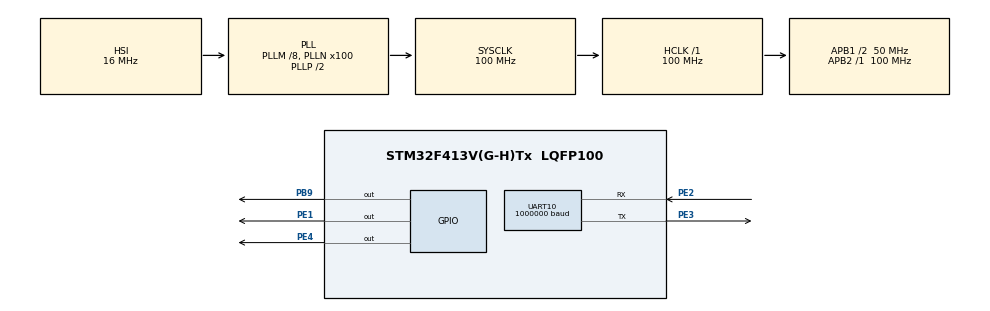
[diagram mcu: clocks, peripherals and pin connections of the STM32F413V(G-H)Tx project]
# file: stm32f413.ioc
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Mcu.Family=STM32F4
Mcu.Name=STM32F413V(G-H)Tx
Mcu.Package=LQFP100
NVIC.PriorityGroup=NVIC_PRIORITYGROUP_4
PB3.Signal=SYS_JTDO-SWO
PB9.Signal=GPIO_Output
PE1.Signal=GPIO_Output
PE2.Mode=Asynchronous
PE2.Signal=UART10_RX
PE3.Mode=Asynchronous
PE3.Signal=UART10_TX
PE4.Signal=GPIO_Output
PH0\ -\ OSC_IN.Mode=HSE-External-Oscillator
PH0\ -\ OSC_IN.Signal=RCC_OSC_IN
PH1\ -\ OSC_OUT.Mode=HSE-External-Oscillator
PH1\ -\ OSC_OUT.Signal=RCC_OSC_OUT
ProjectManager.HeapSize=0x2000
ProjectManager.StackSize=0x4000
ProjectManager.TargetToolchain=Makefile
RCC.AHBFreq_Value=100000000
RCC.APB1CLKDivider=RCC_HCLK_DIV2
RCC.APB1Freq_Value=50000000
RCC.APB1TimFreq_Value=100000000
RCC.APB2Freq_Value=100000000
RCC.APB2TimFreq_Value=100000000
RCC.CortexFreq_Value=100000000
RCC.HCLKFreq_Value=100000000
RCC.HSE_VALUE=8000000
RCC.PLLM=8
RCC.PLLN=100
RCC.SYSCLKFreq_VALUE=100000000
RCC.SYSCLKSource=RCC_SYSCLKSOURCE_PLLCLK
RCC.USBFreq_Value=100000000
RCC.VCOOutputFreq_Value=200000000
UART10.BaudRate=1000000
UART10.VirtualMode=Asynchronous
board=custom

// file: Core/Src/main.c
/* USER CODE BEGIN Header */
/**
  ******************************************************************************
  * @file           : main.c
  * @brief          : Main program body
  ******************************************************************************
  * @attention
  *
  * <h2><center>&copy; Copyright (c) 2021 STMicroelectronics.
  * All rights reserved.</center></h2>
  *
  * This software component is licensed by ST under BSD 3-Clause license,
  * the "License"; You may not use this file except in compliance with the
  * License. You may obtain a copy of the License at:
  *                        opensource.org/licenses/BSD-3-Clause
  *
  ******************************************************************************
  */
/* USER CODE END Header */
#include "main.h"

/* USER CODE BEGIN Includes */
extern void application_main();
/* USER CODE END Includes */

UART_HandleTypeDef huart10;

void SystemClock_Config(void);
static void MX_GPIO_Init(void);
static void MX_UART10_Init(void);

int main(void)
{

  /* MCU Configuration--------------------------------------------------------*/

  /* Reset of all peripherals, Initializes the Flash interface and the Systick. */
  HAL_Init();

  /* Configure the system clock */
  SystemClock_Config();

  /* Initialize all configured peripherals */
  MX_GPIO_Init();
  MX_UART10_Init();
  /* USER CODE BEGIN 2 */
  application_main();
  /* USER CODE END 2 */

  /* Infinite loop */
  while (1)
  {

  }
}

void SystemClock_Config(void)
{
  RCC_OscInitTypeDef RCC_OscInitStruct = {0};
  RCC_ClkInitTypeDef RCC_ClkInitStruct = {0};

  /** Configure the main internal regulator output voltage
  */
  __HAL_RCC_PWR_CLK_ENABLE();
  __HAL_PWR_VOLTAGESCALING_CONFIG(PWR_REGULATOR_VOLTAGE_SCALE1);
  /** Initializes the RCC Oscillators according to the specified parameters
  * in the RCC_OscInitTypeDef structure.
  */
  RCC_OscInitStruct.OscillatorType = RCC_OSCILLATORTYPE_HSI;
  RCC_OscInitStruct.HSIState = RCC_HSI_ON;
  RCC_OscInitStruct.HSICalibrationValue = RCC_HSICALIBRATION_DEFAULT;
  RCC_OscInitStruct.PLL.PLLState = RCC_PLL_ON;
  RCC_OscInitStruct.PLL.PLLSource = RCC_PLLSOURCE_HSI;
  RCC_OscInitStruct.PLL.PLLM = 8;
  RCC_OscInitStruct.PLL.PLLN = 100;
  RCC_OscInitStruct.PLL.PLLP = RCC_PLLP_DIV2;
  RCC_OscInitStruct.PLL.PLLQ = 2;
  RCC_OscInitStruct.PLL.PLLR = 2;
  if (HAL_RCC_OscConfig(&RCC_OscInitStruct) != HAL_OK)
  {
    Error_Handler();
  }
  /** Initializes the CPU, AHB and APB buses clocks
  */
  RCC_ClkInitStruct.ClockType = RCC_CLOCKTYPE_HCLK|RCC_CLOCKTYPE_SYSCLK
                              |RCC_CLOCKTYPE_PCLK1|RCC_CLOCKTYPE_PCLK2;
  RCC_ClkInitStruct.SYSCLKSource = RCC_SYSCLKSOURCE_PLLCLK;
  RCC_ClkInitStruct.AHBCLKDivider = RCC_SYSCLK_DIV1;
  RCC_ClkInitStruct.APB1CLKDivider = RCC_HCLK_DIV2;
  RCC_ClkInitStruct.APB2CLKDivider = RCC_HCLK_DIV1;

  if (HAL_RCC_ClockConfig(&RCC_ClkInitStruct, FLASH_LATENCY_3) != HAL_OK)
  {
    Error_Handler();
  }
}

static void MX_UART10_Init(void)
{

  huart10.Instance = UART10;
  huart10.Init.BaudRate = 1000000;
  huart10.Init.WordLength = UART_WORDLENGTH_8B;
  huart10.Init.StopBits = UART_STOPBITS_1;
  huart10.Init.Parity = UART_PARITY_NONE;
  huart10.Init.Mode = UART_MODE_TX_RX;
  huart10.Init.HwFlowCtl = UART_HWCONTROL_NONE;
  huart10.Init.OverSampling = UART_OVERSAMPLING_16;
  if (HAL_UART_Init(&huart10) != HAL_OK)
  {
    Error_Handler();
  }

}

static void MX_GPIO_Init(void)
{
  GPIO_InitTypeDef GPIO_InitStruct = {0};

  /* GPIO Ports Clock Enable */
  __HAL_RCC_GPIOE_CLK_ENABLE();
  __HAL_RCC_GPIOH_CLK_ENABLE();
  __HAL_RCC_GPIOB_CLK_ENABLE();

  /*Configure GPIO pin Output Level */
  HAL_GPIO_WritePin(GPIOE, GPIO_PIN_4|GPIO_PIN_1, GPIO_PIN_RESET);

  /*Configure GPIO pin Output Level */
  HAL_GPIO_WritePin(GPIOB, GPIO_PIN_9, GPIO_PIN_RESET);

  /*Configure GPIO pins : PE4 PE1 */
  GPIO_InitStruct.Pin = GPIO_PIN_4|GPIO_PIN_1;
  GPIO_InitStruct.Mode = GPIO_MODE_OUTPUT_PP;
  GPIO_InitStruct.Pull = GPIO_NOPULL;
  GPIO_InitStruct.Speed = GPIO_SPEED_FREQ_LOW;
  HAL_GPIO_Init(GPIOE, &GPIO_InitStruct);

  /*Configure GPIO pin : PB9 */
  GPIO_InitStruct.Pin = GPIO_PIN_9;
  GPIO_InitStruct.Mode = GPIO_MODE_OUTPUT_PP;
  GPIO_InitStruct.Pull = GPIO_NOPULL;
  GPIO_InitStruct.Speed = GPIO_SPEED_FREQ_LOW;
  HAL_GPIO_Init(GPIOB, &GPIO_InitStruct);

}

void Error_Handler(void)
{
  __disable_irq();
  while (1)
  {
  }
}

/************************ (C) COPYRIGHT STMicroelectronics *****END OF FILE****/
